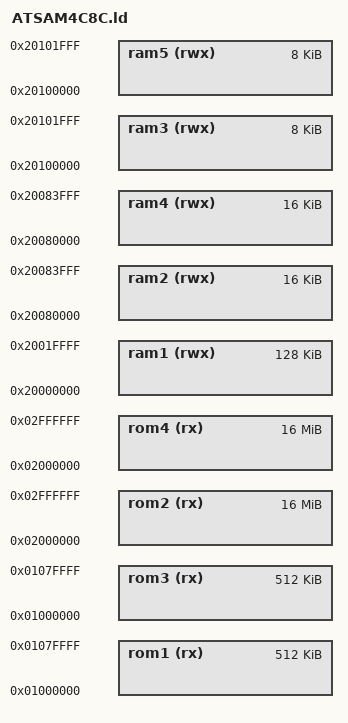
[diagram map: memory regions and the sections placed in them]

MEMORY
{
  rom1 (rx) : ORIGIN = 0x01000000, LENGTH = 0x00080000
  rom2 (rx) : ORIGIN = 0x02000000, LENGTH = 0x01000000
  rom3 (rx) : ORIGIN = 0x01000000, LENGTH = 0x00080000
  rom4 (rx) : ORIGIN = 0x02000000, LENGTH = 0x01000000
  ram1 (rwx) : ORIGIN = 0x20000000, LENGTH = 0x00020000
  ram2 (rwx) : ORIGIN = 0x20080000, LENGTH = 0x00004000
  ram3 (rwx) : ORIGIN = 0x20100000, LENGTH = 0x00002000
  ram4 (rwx) : ORIGIN = 0x20080000, LENGTH = 0x00004000
  ram5 (rwx) : ORIGIN = 0x20100000, LENGTH = 0x00002000
}

